# WB32F10x register map
File version: 1.2
CPU: CM3 r2p0, little endian, MPU, no FPU, 4 interrupt priority bits
Registers are 32-bit, read-write, reset 0x0 unless marked. A register's access mark holds for its fields unless they carry their own. Offsets are from the block's base; [hi:lo] are bit positions; {n}, {i} and the like mark numbered series.

## ANCTL — Analog control
Base 0x40010400
0x1C BGCR2 — BG control register 2
  [1] TEMPOUTEN — Bandgap temperature sensor output enable
0x2C MHSIENR reset 0x1 — MHSI enable register
  [0] MHSION — Internal MHSI enable
0x30 MHSISR ro reset 0x1 — MHSI enable register
  [0] MHSIRDY — Internal MHSI output status
0x38 FHSIENR reset 0x1 — FHSI enable register
  [0] FHSION — Internal FHSI enable control
0x3C FHSISR ro reset 0x1 — FHSI Status register
  [0] FHSIRDY — Internal FHSI clock output status
0x44 LSIENR — LSI enable register
  [0] LSION — Internal LSI enable
0x48 LSISR ro — LSI Status register
  [0] LSIRDY — Internal LSI clock output Status
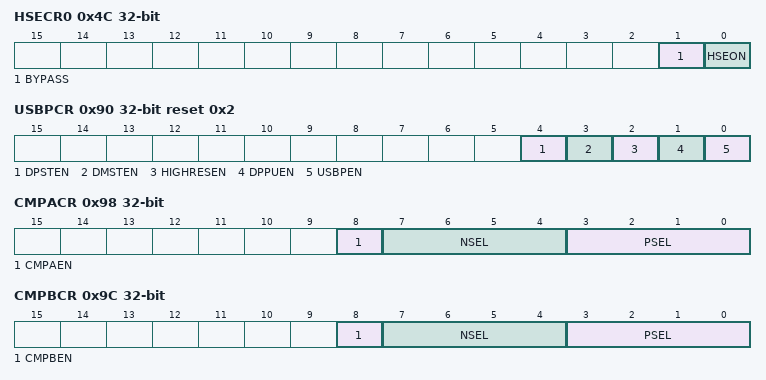
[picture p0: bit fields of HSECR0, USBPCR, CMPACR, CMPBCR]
0x4C HSECR0 — HSE control register 0
  [1] BYPASS — External clock input mode enable
  [0] HSEON — HSE enable
0x50 HSECR1 — HSE control register 1
  [1] PADOEN — HSE clock loop back from PAD
0x58 HSESR ro — HSE Status register
  [0] HSERDY — HSE clock output Status
0x74 PLLCR — PLL control register
  [7:6] PLLMUL — PLL multiplier factor
0x78 PLLENR — PLL enable control register
  [0] PLLON — PLL enable control
0x7C PLLSR ro — PLL Status register
  [1:0] PLLRDY — PLL clock output Status
0x80 PVDCR reset 0x4 — PVD control register
  [2:0] PLS — PVD threshold voltage selection
0x84 PVDENR — PVD enable register
  [0] PVDE — PVD enable control
0x8C SARENR reset 0x1E — SARADC enable register
  [0] SAREN — SARADC enable control
0x90 USBPCR reset 0x2 — USB PHY control register
  [4] DPSTEN — DP Schmidt enable
  [3] DMSTEN — DM Schmidt enable
  [2] HIGHRESEN — High resistance enable
  [1] DPPUEN — DP pull enable
  [0] USBPEN — USB PHY enable
0x94 PORCR reset 0x841 — POR control register
  [11:0] POREN — POR enable control
0x98 CMPACR — CMPA control register
  [8] CMPAEN — CMPA enable control
  [7:4] NSEL — CMPA negative input channel selection
  [3:0] PSEL — CMPA positive input channel selection
0x9C CMPBCR — CMPB control register
  [8] CMPBEN — CMPB enable control
  [7:4] NSEL — CMPB negative input channel selection
  [3:0] PSEL — CMPB positive input channel selection
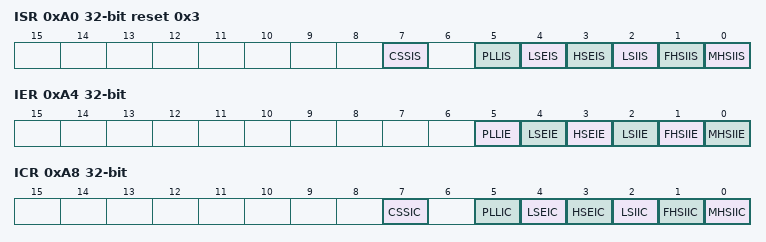
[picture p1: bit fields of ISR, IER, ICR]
0xA0 ISR ro reset 0x3 — INT Status register
  [7] CSSIS — HSE clock failure detection interrupt flag
  [5] PLLIS — PLL clock output stable flag
  [4] LSEIS — LSE clock output stable flag
  [3] HSEIS — HSE clock output stable flag
  [2] LSIIS — LSI clock output stable flag
  [1] FHSIIS — FHSI clock output stable flag
  [0] MHSIIS — MHSI clock output stable flag
0xA4 IER — INT enable register
  [5] PLLIE — PLL clock stable interrupt enable
  [4] LSEIE — LSE clock stable interrupt enable
  [3] HSEIE — HSE clock stable interrupt enable
  [2] LSIIE — LSI clock stable interrupt enable
  [1] FHSIIE — FHSI clock stable interrupt enable
  [0] MHSIIE — MHSI clock stable interrupt enable
0xA8 ICR — INT clear register
  [7] CSSIC — clear HSE clock failure detection interrupt flag
  [5] PLLIC — clear PLL clock output stable interrupt flag
  [4] LSEIC — clear LSE clock output stable interrupt flag
  [3] HSEIC — clear HSE clock output stable interrupt flag
  [2] LSIIC — clear LSI clock output stable interrupt flag
  [1] FHSIIC — clear FHSI clock output stable interrupt flag
  [0] MHSIIC — clear MHSI clock output stable interrupt flag
0xAC CMPASR ro — CMPA Status register
  [0] CMPAOUT — CMPA comparison result
0xB0 CMPBSR ro — CMPB Status register
  [0] CMPBOUT — CMPB comparison result
0xB4 CSSENR — CSS enable register
  [0] CSSON — HSE clock failure detection control
0xB8 CSSCR — CSS configuration register
  [11:0] FREQCNT — Configure CSS count value, must be configured to 0x03

## LED — LED driver controller
Base 0x4000BC00
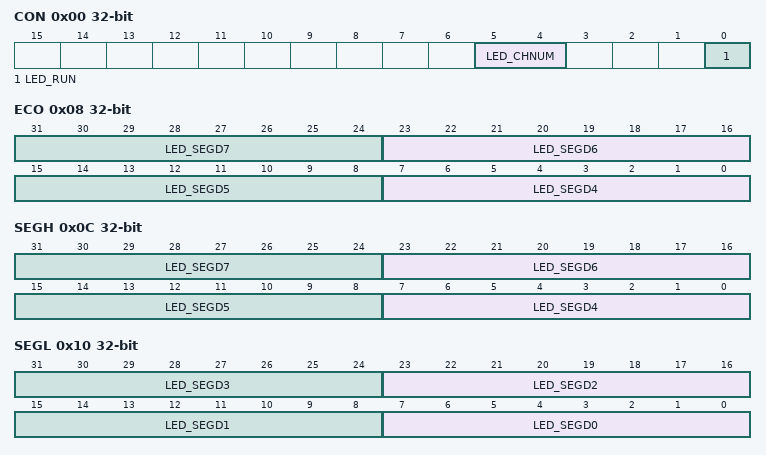
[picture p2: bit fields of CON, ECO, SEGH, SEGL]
0x00 CON — Control register
  [5:4] LED_CHNUM — LED chanel number
  [0] LED_RUN — LED enable
0x04 CYC — Cycle register
  [15:0] LED_CYC — LED cycle
0x08 ECO — Electric output register
  [8n-25:8n-32] LED_SEGD{n} (n=4..7) — Segment {n} control output bits
0x0C SEGH — Segment control high register
  [8n-25:8n-32] LED_SEGD{n} (n=4..7) — Segment {n} control output bits
0x10 SEGL — Segment control low register
  [8n+7:8n] LED_SEGD{n} (n=0..3) — Segment {n} control output bits
